# CC1350F128 register map
File version: 1.0
CPU: CM3 1.0, other endian, MPU, FPU, 3 interrupt priority bits
Registers are 32-bit, read-write, reset 0x0 unless marked. A register's access mark holds for its fields unless they carry their own. Offsets are from the block's base; [hi:lo] are bit positions; {n}, {i} and the like mark numbered series.

## CPU_FPB — Cortex-M's Flash Patch and Breakpoint (FPB)
Base 0xE0002000
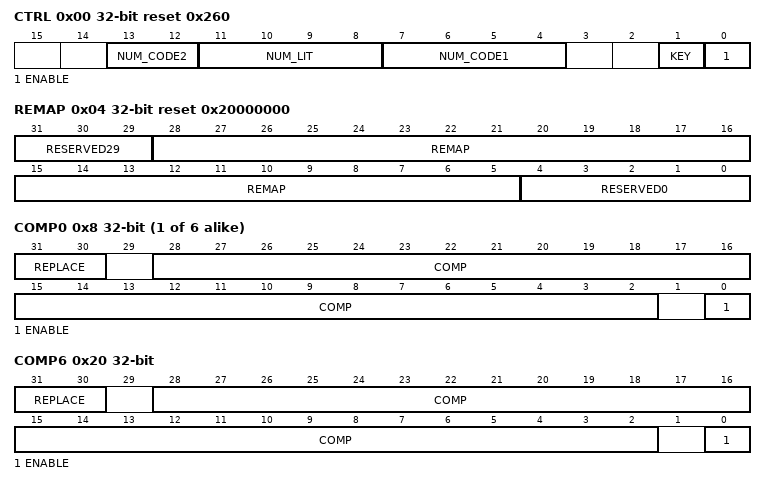
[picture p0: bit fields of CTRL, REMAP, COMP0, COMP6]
0x00 CTRL reset 0x260 — Control This register is used to enable the flash patch block.
  [13:12] NUM_CODE2 ro — [13:12] Number of full banks of code comparators, sixteen comparators per bank. Where less than sixteen code comparators are provided, the bank count is zero, and the number present indicated by NUM_CODE1. This read only field contains 3'b000 to indicate 0 banks for Cortex-M processor.
  [11:8] NUM_LIT ro — [11:8] Number of literal slots field. 0x0: No literal slots 0x2: Two literal slots
  [7:4] NUM_CODE1 ro — [7:4] Number of code slots field. 0x0: No code slots 0x2: Two code slots 0x6: Six code slots
  [1] KEY wo — [1:1] Key field. In order to write to this register, this bit-field must be written to '1'. This bit always reads 0.
  [0] ENABLE — [0:0] Flash patch unit enable bit 0x0: Flash patch unit disabled 0x1: Flash patch unit enabled
0x04 REMAP reset 0x20000000 — Remap This register provides the remap base address location where a matched addresses are remapped. The three most significant bits and the five least significant bits of the remap base address are hard-coded to 3'b001 and 5'b00000 respectively. The remap base address must be in system space and is it required to be 8-word aligned, with one word allocated to each of the eight FPB comparators.
  [31:29] RESERVED29 ro — [31:29] This field always reads 3'b001. Writing to this field is ignored.
  [28:5] REMAP — [28:5] Remap base address field.
  [4:0] RESERVED0 ro — [4:0] This field always reads 0. Writing to this field is ignored.
{0x8+4i} COMP{i} (i=0..5) — Comparator {i}
  [31:30] REPLACE — [31:30] This selects what happens when the COMP address is matched. Address remapping only takes place for the 0x0 setting. 0x0: Remap to remap address. See REMAP.REMAP 0x1: Set BKPT on lower halfword, upper is unaffected 0x2: Set BKPT on upper halfword, lower is unaffected 0x3: Set BKPT on both lower and upper halfwords.
  [28:2] COMP — [28:2] Comparison address.
  [0] ENABLE — [0:0] Compare and remap enable comparator {i}. CTRL.ENABLE must also be set to enable comparisons. 0x0: Compare and remap for comparator {i} disabled 0x1: Compare and remap for comparator {i} enabled
0x20 COMP6 — Comparator 6
  [31:30] REPLACE — [31:30] This selects what happens when the COMP address is matched. Comparator 6 is a literal comparator and the only supported setting is 0x0. Other settings will be ignored. 0x0: Remap to remap address. See REMAP.REMAP 0x1: Set BKPT on lower halfword, upper is unaffected 0x2: Set BKPT on upper halfword, lower is unaffected 0x3: Set BKPT on both lower and upper halfwords.
  [28:2] COMP — [28:2] Comparison address.
  [0] ENABLE — [0:0] Compare and remap enable comparator 6. CTRL.ENABLE must also be set to enable comparisons. 0x0: Compare and remap for comparator 6 disabled 0x1: Compare and remap for comparator 6 enabled
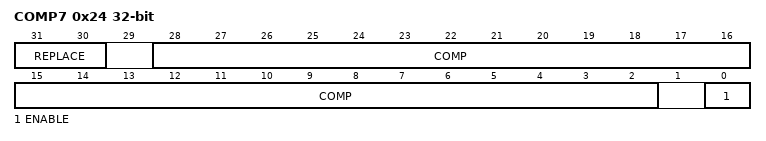
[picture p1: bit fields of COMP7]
0x24 COMP7 — Comparator 7
  [31:30] REPLACE — [31:30] This selects what happens when the COMP address is matched. Comparator 7 is a literal comparator and the only supported setting is 0x0. Other settings will be ignored. 0x0: Remap to remap address. See REMAP.REMAP 0x1: Set BKPT on lower halfword, upper is unaffected 0x2: Set BKPT on upper halfword, lower is unaffected 0x3: Set BKPT on both lower and upper halfwords.
  [28:2] COMP — [28:2] Comparison address.
  [0] ENABLE — [0:0] Compare and remap enable comparator 7. CTRL.ENABLE must also be set to enable comparisons. 0x0: Compare and remap for comparator 7 disabled 0x1: Compare and remap for comparator 7 enabled

## CPU_TIPROP — Cortex-M's TI proprietary registers
Base 0xE00FE000
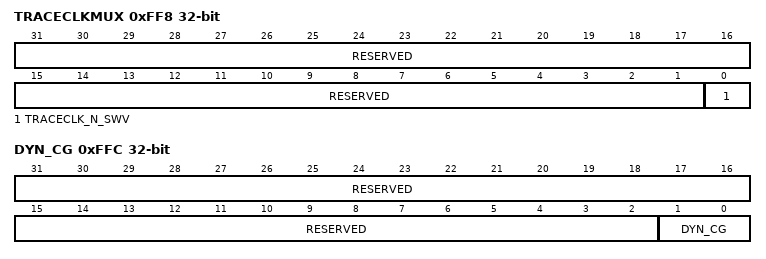
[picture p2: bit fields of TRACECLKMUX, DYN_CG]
0xFF8 TRACECLKMUX — Internal. Only to be used through TI provided API.
  [31:1] RESERVED ro — [31:1] Internal. Only to be used through TI provided API.
  [0] TRACECLK_N_SWV — [0:0] Internal. Only to be used through TI provided API.
    1=TRACECLK (Internal. Only to be used through TI provided API.); 0=SWV (Internal. Only to be used through TI provided API.)
0xFFC DYN_CG — Internal. Only to be used through TI provided API.
  [31:2] RESERVED ro — [31:2] Internal. Only to be used through TI provided API.
  [1:0] DYN_CG — [1:0] Internal. Only to be used through TI provided API.
